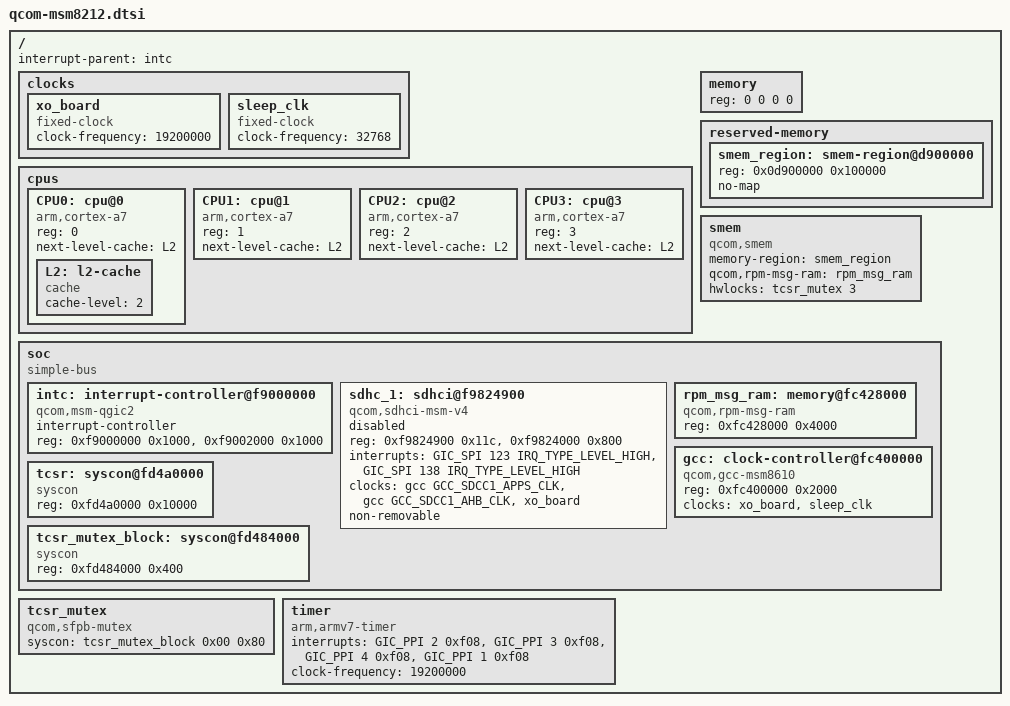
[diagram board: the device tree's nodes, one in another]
// SPDX-License-Identifier: BSD-3-Clause
/*
 * Copyright (c) 2021, Ivaylo Ivanov <ivo.ivanov@null.net>
 * Copyright (c) 2021, Konrad Dybcio <konrad.dybcio@somainline.org>
 */
/dts-v1/;

#include <dt-bindings/interrupt-controller/arm-gic.h>
#include <dt-bindings/reset/qcom,gcc-msm8610.h>
#include <dt-bindings/clock/qcom,gcc-msm8610.h>

/ {
	interrupt-parent = <&intc>;
	
	#address-cells = <1>;
	#size-cells = <1>;

	clocks {
		xo_board: xo_board {
			compatible = "fixed-clock";
			#clock-cells = <0>;
			clock-frequency = <19200000>;
		};

		sleep_clk: sleep_clk {
			compatible = "fixed-clock";
			#clock-cells = <0>;
			clock-frequency = <32768>;
		};
	};

	cpus {
		#address-cells = <1>;
		#size-cells = <0>;

		CPU0: cpu@0 {
			compatible = "arm,cortex-a7";
			device_type = "cpu";
			reg = <0>;
			next-level-cache = <&L2>;

			L2: l2-cache {
				compatible = "cache";
				cache-level = <2>;
			};
		};

		CPU1: cpu@1 {
			compatible = "arm,cortex-a7";
			device_type = "cpu";
			reg = <1>;
			next-level-cache = <&L2>;
		};

		CPU2: cpu@2 {
			compatible = "arm,cortex-a7";
			device_type = "cpu";
			reg = <2>;
			next-level-cache = <&L2>;
		};

		CPU3: cpu@3 {
			compatible = "arm,cortex-a7";
			device_type = "cpu";
			reg = <3>;
			next-level-cache = <&L2>;
		};
	};

	memory {
		device_type = "memory";
		/* We expect the bootloader to fill in the reg */
		reg = <0 0 0 0>;
	};
	
	reserved-memory {
		#address-cells = <1>;
		#size-cells = <1>;
		ranges;
		
		smem_region: smem-region@d900000 {
			reg = <0x0d900000 0x100000>;
			no-map;
		};
	};
	
	smem {
		compatible = "qcom,smem";
		memory-region = <&smem_region>;
		qcom,rpm-msg-ram = <&rpm_msg_ram>;
		hwlocks = <&tcsr_mutex 3>;
	};

	soc {
		#address-cells = <1>;
		#size-cells = <1>;
		ranges;
		compatible = "simple-bus";

		intc: interrupt-controller@f9000000 {
			compatible = "qcom,msm-qgic2";
			interrupt-controller;
			#interrupt-cells = <3>;
			reg = <0xf9000000 0x1000>,
			      <0xf9002000 0x1000>;
		};
		
		sdhc_1: sdhci@f9824900 {
			compatible = "qcom,sdhci-msm-v4";
			reg = <0xf9824900 0x11c>, <0xf9824000 0x800>;
			reg-names = "hc_mem", "core_mem";

			interrupts = <GIC_SPI 123 IRQ_TYPE_LEVEL_HIGH>,
					<GIC_SPI 138 IRQ_TYPE_LEVEL_HIGH>;
			interrupt-names = "hc_irq", "pwr_irq";

			clocks = <&gcc GCC_SDCC1_APPS_CLK>,
				<&gcc GCC_SDCC1_AHB_CLK>,
				<&xo_board>;
			clock-names = "core", "iface", "xo";

			non-removable;

			status = "disabled";
		};
		
		rpm_msg_ram: memory@fc428000 {
			compatible = "qcom,rpm-msg-ram";
			reg = <0xfc428000 0x4000>;
		};

		gcc: clock-controller@fc400000 {
                        compatible = "qcom,gcc-msm8610";
                        #clock-cells = <1>;
                        #reset-cells = <1>;
                        #power-domain-cells = <1>;
                        reg = <0xfc400000 0x2000>;
                        clocks = <&xo_board>, <&sleep_clk>;
                        clock-names = "xo", "sleep";
                };

		tcsr: syscon@fd4a0000 {
			compatible = "syscon";
			reg = <0xfd4a0000 0x10000>;
		};

		tcsr_mutex_block: syscon@fd484000 {
			compatible = "syscon";
			reg = <0xfd484000 0x400>;
		};
	};

	tcsr_mutex: tcsr_mutex {
		compatible = "qcom,sfpb-mutex";
		syscon = <&tcsr_mutex_block 0x00 0x80>;
		#hwlock-cells = <1>;
	};
		
	timer {
		compatible = "arm,armv7-timer";
		interrupts = <GIC_PPI 2 0xf08>,
			     <GIC_PPI 3 0xf08>,
			     <GIC_PPI 4 0xf08>,
			     <GIC_PPI 1 0xf08>;
		clock-frequency = <19200000>;
	};
};
